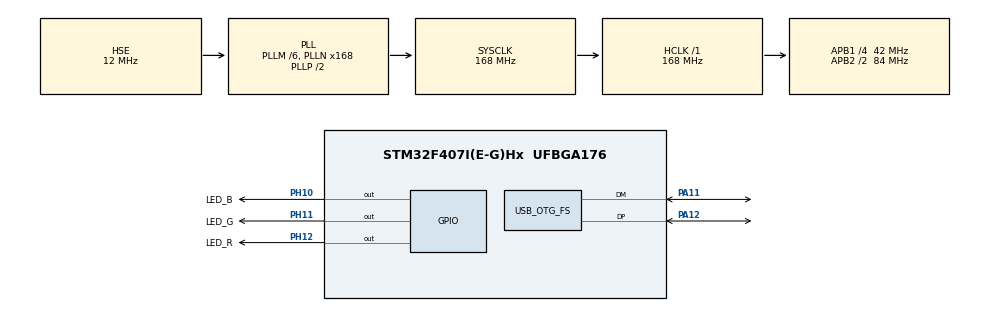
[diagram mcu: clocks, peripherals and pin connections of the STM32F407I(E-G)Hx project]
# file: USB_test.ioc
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FREERTOS.INCLUDE_vTaskDelayUntil=1
FREERTOS.Tasks01=defaultTask,0,128,StartDefaultTask,Default,NULL,Dynamic,NULL,NULL
Mcu.Family=STM32F4
Mcu.Name=STM32F407I(E-G)Hx
Mcu.Package=UFBGA176
NVIC.OTG_FS_IRQn=true\:5\:0\:false\:false\:true\:true\:false\:true\:true
NVIC.PriorityGroup=NVIC_PRIORITYGROUP_4
NVIC.TIM8_TRG_COM_TIM14_IRQn=true\:15\:0\:false\:false\:true\:false\:false\:true\:true
NVIC.TimeBase=TIM8_TRG_COM_TIM14_IRQn
NVIC.TimeBaseIP=TIM14
PA11.Mode=Device_Only
PA11.Signal=USB_OTG_FS_DM
PA12.Mode=Device_Only
PA12.Signal=USB_OTG_FS_DP
PA13.Mode=Serial_Wire
PA13.Signal=SYS_JTMS-SWDIO
PA14.Mode=Serial_Wire
PA14.Signal=SYS_JTCK-SWCLK
PC14-OSC32_IN.Mode=LSE-External-Oscillator
PC14-OSC32_IN.Signal=RCC_OSC32_IN
PC15-OSC32_OUT.Mode=LSE-External-Oscillator
PC15-OSC32_OUT.Signal=RCC_OSC32_OUT
PH0-OSC_IN.Mode=HSE-External-Oscillator
PH0-OSC_IN.Signal=RCC_OSC_IN
PH1-OSC_OUT.Mode=HSE-External-Oscillator
PH1-OSC_OUT.Signal=RCC_OSC_OUT
PH10.GPIO_Label=LED_B
PH10.Signal=GPIO_Output
PH11.GPIO_Label=LED_G
PH11.Signal=GPIO_Output
PH12.GPIO_Label=LED_R
PH12.Signal=GPIO_Output
ProjectManager.HeapSize=0x2000
ProjectManager.StackSize=0x4000
ProjectManager.TargetToolchain=MDK-ARM V5.32
RCC.48MHZClocksFreq_Value=48000000
RCC.AHBFreq_Value=168000000
RCC.APB1CLKDivider=RCC_HCLK_DIV4
RCC.APB1Freq_Value=42000000
RCC.APB1TimFreq_Value=84000000
RCC.APB2CLKDivider=RCC_HCLK_DIV2
RCC.APB2Freq_Value=84000000
RCC.APB2TimFreq_Value=168000000
RCC.CortexFreq_Value=168000000
RCC.HCLKFreq_Value=168000000
RCC.HSE_VALUE=12000000
RCC.HSI_VALUE=16000000
RCC.PLLM=6
RCC.PLLN=168
RCC.PLLQ=7
RCC.SYSCLKFreq_VALUE=168000000
RCC.SYSCLKSource=RCC_SYSCLKSOURCE_PLLCLK
RCC.VCOOutputFreq_Value=336000000
STMicroelectronics.X-CUBE-ALGOBUILD.1.5.0.LibraryCcDSPOoLibraryJjDSPOoLibrary=true
USB_DEVICE.CLASS_NAME_FS=CDC
USB_DEVICE.VID-CDC_FS=200
USB_DEVICE.VirtualMode-CDC_FS=Cdc
USB_DEVICE.VirtualModeFS=Cdc_FS
USB_OTG_FS.VirtualMode=Device_Only
VP_FREERTOS_VS_CMSIS_V1.Mode=CMSIS_V1
VP_STMicroelectronics.X-CUBE-ALGOBUILD_VS_DSPOoLibraryJjLibrary_1.5.0_1.5.0.Mode=DSPOoLibraryJjLibrary
VP_SYS_VS_tim14.Mode=TIM14
VP_USB_DEVICE_VS_USB_DEVICE_CDC_FS.Mode=CDC_FS
board=custom

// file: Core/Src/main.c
/* USER CODE BEGIN Header */
/**
  ******************************************************************************
  * @file           : main.c
  * @brief          : Main program body
  ******************************************************************************
  * @attention
  *
  * Copyright (c) 2026 STMicroelectronics.
  * All rights reserved.
  *
  * This software is licensed under terms that can be found in the LICENSE file
  * in the root directory of this software component.
  * If no LICENSE file comes with this software, it is provided AS-IS.
  *
  ******************************************************************************
  */
/* USER CODE END Header */
#include "main.h"
#include "cmsis_os.h"
#include "usb_device.h"
#include "gpio.h"

void SystemClock_Config(void);
void MX_FREERTOS_Init(void);

int main(void)
{

  /* MCU Configuration--------------------------------------------------------*/

  /* Reset of all peripherals, Initializes the Flash interface and the Systick. */
  HAL_Init();

  /* Configure the system clock */
  SystemClock_Config();

  /* Initialize all configured peripherals */
  MX_GPIO_Init();

  /* Call init function for freertos objects (in cmsis_os2.c) */
  MX_FREERTOS_Init();

  /* Start scheduler */
  osKernelStart();

  /* We should never get here as control is now taken by the scheduler */

  /* Infinite loop */
  while (1)
  {

  }
}

void SystemClock_Config(void)
{
  RCC_OscInitTypeDef RCC_OscInitStruct = {0};
  RCC_ClkInitTypeDef RCC_ClkInitStruct = {0};

  /** Configure the main internal regulator output voltage
  */
  __HAL_RCC_PWR_CLK_ENABLE();
  __HAL_PWR_VOLTAGESCALING_CONFIG(PWR_REGULATOR_VOLTAGE_SCALE1);

  /** Initializes the RCC Oscillators according to the specified parameters
  * in the RCC_OscInitTypeDef structure.
  */
  RCC_OscInitStruct.OscillatorType = RCC_OSCILLATORTYPE_HSE;
  RCC_OscInitStruct.HSEState = RCC_HSE_ON;
  RCC_OscInitStruct.PLL.PLLState = RCC_PLL_ON;
  RCC_OscInitStruct.PLL.PLLSource = RCC_PLLSOURCE_HSE;
  RCC_OscInitStruct.PLL.PLLM = 6;
  RCC_OscInitStruct.PLL.PLLN = 168;
  RCC_OscInitStruct.PLL.PLLP = RCC_PLLP_DIV2;
  RCC_OscInitStruct.PLL.PLLQ = 7;
  if (HAL_RCC_OscConfig(&RCC_OscInitStruct) != HAL_OK)
  {
    Error_Handler();
  }

  /** Initializes the CPU, AHB and APB buses clocks
  */
  RCC_ClkInitStruct.ClockType = RCC_CLOCKTYPE_HCLK|RCC_CLOCKTYPE_SYSCLK
                              |RCC_CLOCKTYPE_PCLK1|RCC_CLOCKTYPE_PCLK2;
  RCC_ClkInitStruct.SYSCLKSource = RCC_SYSCLKSOURCE_PLLCLK;
  RCC_ClkInitStruct.AHBCLKDivider = RCC_SYSCLK_DIV1;
  RCC_ClkInitStruct.APB1CLKDivider = RCC_HCLK_DIV4;
  RCC_ClkInitStruct.APB2CLKDivider = RCC_HCLK_DIV2;

  if (HAL_RCC_ClockConfig(&RCC_ClkInitStruct, FLASH_LATENCY_5) != HAL_OK)
  {
    Error_Handler();
  }
}

void HAL_TIM_PeriodElapsedCallback(TIM_HandleTypeDef *htim)
{
  if (htim->Instance == TIM14)
  {
    HAL_IncTick();
  }
}

void Error_Handler(void)
{
  __disable_irq();
  while (1)
  {
  }
}

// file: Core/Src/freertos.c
/* USER CODE BEGIN Header */
/**
  ******************************************************************************
  * File Name          : freertos.c
  * Description        : Code for freertos applications
  ******************************************************************************
  * @attention
  *
  * Copyright (c) 2026 STMicroelectronics.
  * All rights reserved.
  *
  * This software is licensed under terms that can be found in the LICENSE file
  * in the root directory of this software component.
  * If no LICENSE file comes with this software, it is provided AS-IS.
  *
  ******************************************************************************
  */
/* USER CODE END Header */

#include "FreeRTOS.h"
#include "task.h"
#include "main.h"
#include "cmsis_os.h"

/* USER CODE BEGIN Includes */
#include "Task_init.h"
/* USER CODE END Includes */

osThreadId defaultTaskHandle;

void StartDefaultTask(void const * argument);

extern void MX_USB_DEVICE_Init(void);
void MX_FREERTOS_Init(void); /* (MISRA C 2004 rule 8.1) */

/* GetIdleTaskMemory prototype (linked to static allocation support) */
void vApplicationGetIdleTaskMemory( StaticTask_t **ppxIdleTaskTCBBuffer, StackType_t **ppxIdleTaskStackBuffer, uint32_t *pulIdleTaskStackSize );

/* USER CODE BEGIN GET_IDLE_TASK_MEMORY */
static StaticTask_t xIdleTaskTCBBuffer;
static StackType_t xIdleStack[configMINIMAL_STACK_SIZE];

void vApplicationGetIdleTaskMemory( StaticTask_t **ppxIdleTaskTCBBuffer, StackType_t **ppxIdleTaskStackBuffer, uint32_t *pulIdleTaskStackSize )
{
  *ppxIdleTaskTCBBuffer = &xIdleTaskTCBBuffer;
  *ppxIdleTaskStackBuffer = &xIdleStack[0];
  *pulIdleTaskStackSize = configMINIMAL_STACK_SIZE;
  /* place for user code */
}
/* USER CODE END GET_IDLE_TASK_MEMORY */

void MX_FREERTOS_Init(void) {
  /* USER CODE BEGIN Init */
  /* Create RX resources before StartDefaultTask starts the USB device. */
  USB_Rx_Init();

  /* USER CODE END Init */

  /* Create the thread(s) */
  /* definition and creation of defaultTask */
  osThreadDef(defaultTask, StartDefaultTask, osPriorityNormal, 0, 128);
  defaultTaskHandle = osThreadCreate(osThread(defaultTask), NULL);

}

void StartDefaultTask(void const * argument)
{
  /* init code for USB_DEVICE */
  MX_USB_DEVICE_Init();
  /* USER CODE BEGIN StartDefaultTask */
  /* Infinite loop */
  for(;;)
  {
	portENTER_CRITICAL();

	Start_Task();

	portEXIT_CRITICAL();

	vTaskDelete(NULL);
    osDelay(1);
  }
  /* USER CODE END StartDefaultTask */
}
